VERSION ""

NS_ :

BS_:
BU_: Ecoboost
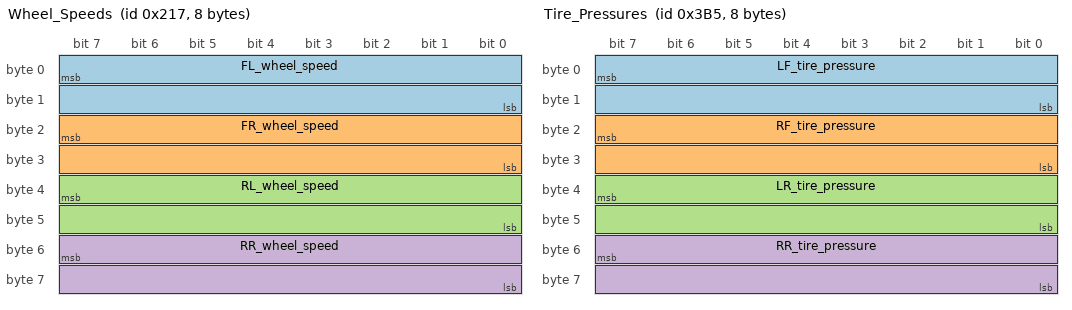
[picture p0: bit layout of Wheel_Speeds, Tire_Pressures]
BO_ 535 Wheel_Speeds: 8 Ecoboost
   SG_ FL_wheel_speed : 7|16@0+ (0.0122076,0) [0|250] "KPH" Vector__XXX
   SG_ FR_wheel_speed : 23|16@0+ (0.0122076,0) [0|250] "KPH" Vector__XXX
   SG_ RL_wheel_speed : 39|16@0+ (0.0122076,0) [0|250] "KPH" Vector__XXX
   SG_ RR_wheel_speed : 55|16@0+ (0.0122076,0) [0|250] "KPH" Vector__XXX

BO_ 125 Brake_Pressure: 8 Ecoboost
   SG_ Brake_Pressure : 4|13@0+ (0.01,0) [0|1] "kPa" Vector__XXX

BO_ 560 Transmission: 8 Ecoboost
   SG_ Gear : 7|4@0+ (1,0) [0|6] "Gear" Vector__XXX

BO_ 949 Tire_Pressures: 8 Ecoboost
   SG_ LF_tire_pressure : 7|16@0+ (0.01,0) [0|1] "kPa" Vector__XXX
   SG_ RF_tire_pressure : 23|16@0+ (0.01,0) [0|1] "kPa" Vector__XXX
   SG_ LR_tire_pressure : 39|16@0+ (0.01,0) [0|1] "kPa" Vector__XXX
   SG_ RR_tire_pressure : 55|16@0+ (0.01,0) [0|1] "kPa" Vector__XXX

BO_ 130 EPS: 8 Ecoboost
   SG_ Drive_mode : 55|8@0+ (1,0) [0|1] "" Vector__XXX

BO_ 376 MSG1: 8 Ecoboost
   SG_ Launch_Ctrl : 6|1@0+ (1,0) [0|1] "" Vector__XXX

BA_DEF_ BO_ "GenMsgBackgroundColor" STRING ;
BA_DEF_ BO_ "GenMsgForegroundColor" STRING ;
BA_DEF_DEF_ "GenMsgBackgroundColor" "#ffffff";
BA_DEF_DEF_ "GenMsgForegroundColor" "#000000";
VAL_ 560 Gear 1 "First" 2 "Second" 3 "Third" 4 "Fourth" 5 "Fifth" 6 "Sixth" 15 "Neutral";
VAL_ 130 Drive_mode 64 "Normal_Mode" 68 "Sport_Mode" 72 "Comfort_Mode";
VAL_ 376 Launch_Ctrl 0 "Launch_Control_Disabled" 1 "Launch_Control_Enabled";
